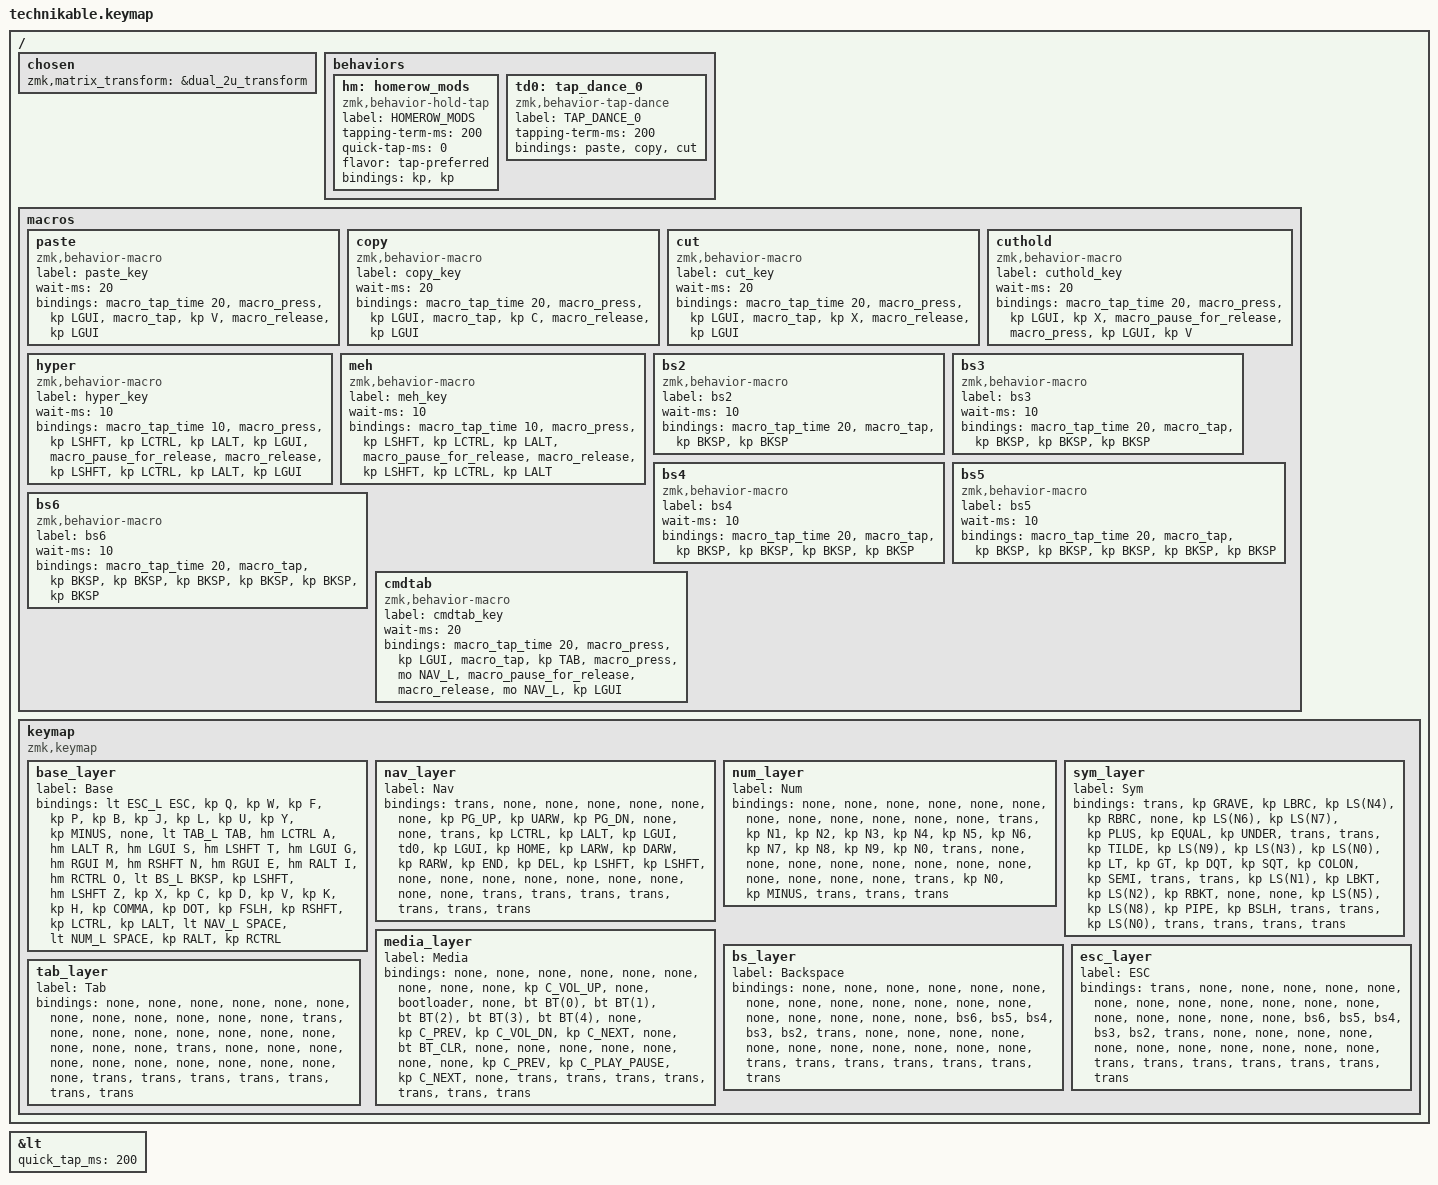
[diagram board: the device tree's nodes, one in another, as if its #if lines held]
/*
 * Copyright (c) 2022 Pete Johanson
 *
 * SPDX-License-Identifier: MIT
 */

#include <behaviors.dtsi>
#include <dt-bindings/zmk/keys.h>
#include <dt-bindings/zmk/bt.h>
#include <dt-bindings/zmk/outputs.h>

#define MOD_TAPS 1

#define TBLE_ORTHO   true
// #define TBLE_MIT     true
// #define TBLE_DUAL_2U true

#define BAS_L 0
#define NAV_L 1
#define NUM_L 2
#define SYM_L 3
#define MEDIA_L 4
#define BS_L 5
#define ESC_L 6
#define TAB_L 7


// Using layer taps on thumbs, having quick tap as well helps w/ repeating space/backspace
&lt { quick_tap_ms = <200>; };

#define BT(n) BT_SEL n

/ {
    chosen {
       zmk,matrix_transform =
#ifdef TBLE_DUAL_2U
                       &dual_2u_transform;
#elif defined(TBLE_MIT)
                       &mit_transform;
#else
                       &ortho_transform;
#endif
    };

    behaviors {
        hm: homerow_mods {
            compatible = "zmk,behavior-hold-tap";
            label = "HOMEROW_MODS";
            #binding-cells = <2>;
            tapping-term-ms = <200>;
            quick-tap-ms = <0>;
            flavor = "tap-preferred";
            bindings = <&kp>, <&kp>;
        };
//        mtmacro: mtmacro {
//            compatible = "zmk,behavior-hold-tap";
//            label = "ModTap_Macros";
//            #binding-cells = <2>;
//            tapping-term-ms = <200>;
//            quick-tap-ms = <0>;
//            flavor = "tap-preferred";
//            bindings = <&>, <&>;
//        };
//        mehd: mehd {
//            compatible = "zmk,behavior-hold-tap";
//            label = "Meh_D";
//            binding-cells = <0>;
//            tapping-term-ms = <200>;
//            quick-tap-ms = <0>;
//            flavor = "tap-preferred";
//            bindings = <&meh>, <&kp D>;
//        };
        td0: tap_dance_0 {
            compatible = "zmk,behavior-tap-dance";
            label = "TAP_DANCE_0";
            #binding-cells = <0>;
            tapping-term-ms = <200>;
            bindings = <&paste>, <&copy>, <&cut>;
        };
    };

    macros {
        paste: paste {
            label = "paste_key";
            compatible = "zmk,behavior-macro";
            #binding-cells = <0>;
            wait-ms = <20>;
            bindings
                = <&macro_tap_time 20>
                , <&macro_press &kp LGUI>
                , <&macro_tap &kp V>
                , <&macro_release &kp LGUI>
                ;
        };
        copy: copy {
            label = "copy_key";
            compatible = "zmk,behavior-macro";
            #binding-cells = <0>;
            wait-ms = <20>;
            bindings
                = <&macro_tap_time 20>
                , <&macro_press &kp LGUI>
                , <&macro_tap &kp C>
                , <&macro_release &kp LGUI>
                ;
        };
        cut: cut {
            label = "cut_key";
            compatible = "zmk,behavior-macro";
            #binding-cells = <0>;
            wait-ms = <20>;
            bindings
                = <&macro_tap_time 20>
                , <&macro_press &kp LGUI>
                , <&macro_tap &kp X>
                , <&macro_release &kp LGUI>
                ;
        };
        cuthold: cuthold {
            label = "cuthold_key";
            compatible = "zmk,behavior-macro";
            #binding-cells = <0>;
            wait-ms = <20>;
            bindings
                = <&macro_tap_time 20>
                , <&macro_press &kp LGUI &kp X>
                , <&macro_pause_for_release>
                , <&macro_press &kp LGUI &kp V>
                ;
        };

        hyper: hyper {
            label = "hyper_key";
            compatible = "zmk,behavior-macro";
            #binding-cells = <0>;
            wait-ms = <10>;
            bindings
                = <&macro_tap_time 10>
                , <&macro_press &kp LSHFT &kp LCTRL &kp LALT &kp LGUI>
                , <&macro_pause_for_release>
                , <&macro_release &kp LSHFT &kp LCTRL &kp LALT &kp LGUI>
                ;
        };
        meh: meh {
            label = "meh_key";
            compatible = "zmk,behavior-macro";
            #binding-cells = <0>;
            wait-ms = <10>;
            bindings
                = <&macro_tap_time 10>
                , <&macro_press &kp LSHFT &kp LCTRL &kp LALT>
                , <&macro_pause_for_release>
                , <&macro_release &kp LSHFT &kp LCTRL &kp LALT>
                ;
        };
        bs2: bs2 {
            label = "bs2";
            compatible = "zmk,behavior-macro";
            #binding-cells = <0>;
            wait-ms = <10>;
            bindings
                = <&macro_tap_time 20>
                , <&macro_tap &kp BKSP &kp BKSP>
                ;
        };
        bs3: bs3 {
            label = "bs3";
            compatible = "zmk,behavior-macro";
            #binding-cells = <0>;
            wait-ms = <10>;
            bindings
                = <&macro_tap_time 20>
                , <&macro_tap &kp BKSP &kp BKSP &kp BKSP>
                ;
        };
        bs4: bs4 {
            label = "bs4";
            compatible = "zmk,behavior-macro";
            #binding-cells = <0>;
            wait-ms = <10>;
            bindings
                = <&macro_tap_time 20>
                , <&macro_tap &kp BKSP &kp BKSP &kp BKSP &kp BKSP>
                ;
        };
        bs5: bs5 {
            label = "bs5";
            compatible = "zmk,behavior-macro";
            #binding-cells = <0>;
            wait-ms = <10>;
            bindings
                = <&macro_tap_time 20>
                , <&macro_tap &kp BKSP &kp BKSP &kp BKSP &kp BKSP &kp BKSP>
                ;
        };
        bs6: bs6 {
            label = "bs6";
            compatible = "zmk,behavior-macro";
            #binding-cells = <0>;
            wait-ms = <10>;
            bindings
                = <&macro_tap_time 20>
                , <&macro_tap &kp BKSP &kp BKSP &kp BKSP &kp BKSP &kp BKSP &kp BKSP>
                ;
        };
        cmdtab: cmdtab {
            label = "cmdtab_key";
            compatible = "zmk,behavior-macro";
            #binding-cells = <0>;
            wait-ms = <20>;
            bindings
                = <&macro_tap_time 20>
                , <&macro_press &kp LGUI>
                , <&macro_tap &kp TAB>
                , <&macro_press &mo NAV_L>
                , <&macro_pause_for_release>
                , <&macro_release &mo NAV_L &kp LGUI>
                ;
        };
    };


//    conditional_layers {
//        compatible = "zmk,conditional-layers";
//	tri_layer {
//	    if-layers = <NAV_L NUM_L>;
//	    then-layer = <SYM_L>;
//	};
//    };

    keymap {
        compatible = "zmk,keymap";

        base_layer {
            label = "Base";
            bindings = <
#ifdef MOD_TAPS
 &lt ESC_L ESC    &kp Q         &kp W      &kp F       &kp P         &kp B          &kp J            &kp L          &kp U       &kp Y       &kp MINUS    &none 
 &lt TAB_L TAB    &hm LCTRL A   &hm LALT R &hm LGUI S  &hm LSHFT T   &hm LGUI G    &hm RGUI M        &hm RSHFT N    &hm RGUI E  &hm RALT I  &hm RCTRL O  &lt BS_L BKSP
 &kp LSHFT  &hm LSHFT Z         &kp X      &kp C       &kp D        &kp V          &kp K            &kp H          &kp COMMA   &kp DOT     &kp FSLH     &kp RSHFT
#else
 &kp ESC    &kp Q      &kp W      &kp F       &kp P          &kp B          &kp J            &kp L          &kp U       &kp Y      &kp MINUS     &none 
 &kp TAB    &kp A      &kp R      &kp S       &kp T          &kp G          &kp M            &kp N          &kp E       &kp I      &kp O        &kp BKSP
 &kp LSHFT  &kp Z      &kp X      &kp C       &kp D          &kp V          &kp K            &kp H          &kp COMMA   &kp DOT    &kp FSLH     &kp RSHFT
#endif
#ifdef TBLE_DUAL_2U
                       &kp LCTRL  &kp LALT      &lt NAV_L SPACE                &lt NUM_L SPACE              &kp RALT    &kp RCTRL
#elif defined(TBLE_MIT)
                       &kp LCTRL  &kp LALT    &mo NAV_L          &kp SPACE                   &mo NUM_L      &kp RALT    &kp RCTRL
#else
                       &meh   &hyper     &mo NAV_L      &kp SPACE      &mo NUM_L         &mo SYM_L      &cmdtab   &none 
#endif
            >;
        };

        nav_layer {
            label = "Nav";
            bindings = <
&trans     &none     &none     &none       &none          &none       &none      &kp PG_UP      &kp UARW       &kp PG_DN    &none      &none 
&trans     &kp LCTRL      &kp LALT      &kp LGUI       &td0        &kp LGUI       &kp HOME      &kp LARW       &kp DARW    &kp RARW   &kp END   &kp DEL
&kp LSHFT     &kp LSHFT      &none      &none       &none       &none        &none       &none        &none    &none    &none    &trans
#ifdef TBLE_DUAL_2U
                      &trans     &trans              &trans                    &trans       &trans         &trans
#elif defined(TBLE_MIT)
                      &trans     &trans      &trans                &trans             &trans      &trans   &trans
#else
                      &trans     &trans      &trans          &trans       &kp RET    &mo MEDIA_L  &trans         &trans
#endif
            >;
        };

        num_layer {
            label = "Num";
            bindings = <
&none    &none   &none     &none      &none   &none    &none    &none         &none       &none       &none     &none
&trans     &kp N1    &kp N2     &kp N3      &kp N4    &kp N5   &kp N6    &kp N7         &kp N8       &kp N9       &kp N0    &trans
&none     &none  &none    &none     &none    &none    &none       &none        &none       &none       &none     &none
#ifdef TBLE_DUAL_2U
                     &trans     &kp N0              &kp MINUS                 &trans            &trans         &trans
#elif defined(TBLE_MIT)
                     &trans     &kp N0      &kp MINUS           &none            &kp ESC        &kp DEL      &trans
#else
                     &trans     &trans     &trans    &trans         &trans     &trans       &trans      &trans
#endif
            >;
        };

        sym_layer {
            label = "Sym";
            bindings = <
&trans     &kp GRAVE   &kp LBRC &kp LS(N4)  &kp RBRC      &none    &kp LS(N6) &kp LS(N7) &kp PLUS       &kp EQUAL   &kp UNDER     &trans
&trans     &kp TILDE  &kp LS(N9) &kp LS(N3)  &kp LS(N0)   &kp LT   &kp GT     &kp DQT      &kp SQT       &kp COLON       &kp SEMI     &trans
&trans     &kp LS(N1)  &kp LBKT &kp LS(N2)  &kp RBKT      &none     &none     &kp LS(N5)      &kp LS(N8)       &kp PIPE       &kp BSLH     &trans
#ifdef TBLE_DUAL_2U
                      &trans     &kp LS(N0)              &trans                    &trans       &trans         &trans
#elif defined(TBLE_MIT)
                      &trans     &kp LS(N0)      &trans                &trans             &trans      &trans   &trans
#else
                      &trans     &kp LS(N0)      &mo MEDIA_L          &kp RET       &trans    &trans  &trans         &trans
#endif
            >;
        };

        media_layer {
            label = "Media";
            bindings = <
&none      &none      &none       &none         &none    &none       &none       &none       &none     &kp C_VOL_UP    &none        &bootloader 
&none        &bt BT(0)  &bt BT(1)  &bt BT(2) &bt BT(3)    &bt BT(4)        &none       &kp C_PREV       &kp C_VOL_DN     &kp C_NEXT    &none           &bt BT_CLR 
&none        &none      &none      &none       &none         &none        &none       &kp C_PREV       &kp C_PLAY_PAUSE     &kp C_NEXT    &none           &trans
#ifdef TBLE_DUAL_2U
                      &trans     &trans              &trans                    &trans       &trans         &trans
#elif defined(TBLE_MIT)
                      &trans     &trans      &trans                &trans             &trans      &trans   &trans
#else
                      &trans     &trans      &trans          &trans       &trans    &trans  &trans         &trans
#endif
            >;
        };
        bs_layer {
            label = "Backspace";
            bindings = <
 &none      &none      &none       &none        &none      &none       &none       &none       &none    &none       &none     &none 
 &none       &none      &none      &none       &none        &none        &bs6        &bs5        &bs4        &bs3    &bs2           &trans
&none        &none      &none      &none       &none         &none        &none        &none        &none        &none   &none           &trans
#ifdef TBLE_DUAL_2U
                      &trans     &trans              &trans                    &trans       &trans         &trans
#elif defined(TBLE_MIT)
                      &trans     &trans      &trans                &trans             &trans      &trans   &trans
#else
                      &trans     &trans      &trans          &trans       &trans    &trans  &trans         &trans
#endif
            >;
        };
        esc_layer {
            label = "ESC";
            bindings = <
 &trans      &none      &none       &none        &none      &none       &none       &none       &none    &none       &none     &none 
 &none       &none      &none      &none       &none        &none        &bs6        &bs5        &bs4        &bs3    &bs2           &trans
&none        &none      &none      &none       &none         &none        &none        &none        &none        &none   &none           &trans
#ifdef TBLE_DUAL_2U
                      &trans     &trans              &trans                    &trans       &trans         &trans
#elif defined(TBLE_MIT)
                      &trans     &trans      &trans                &trans             &trans      &trans   &trans
#else
                      &trans     &trans      &trans          &trans       &trans    &trans  &trans         &trans
#endif
            >;
        };
        tab_layer {
            label = "Tab";
            bindings = <
 &none      &none      &none       &none        &none      &none       &none       &none       &none    &none       &none     &none 
 &trans       &none      &none      &none       &none        &none         &none      &none      &none       &none        &none         &trans
&none        &none      &none      &none       &none         &none        &none        &none        &none        &none   &none           &trans
#ifdef TBLE_DUAL_2U
                      &trans     &trans              &trans                    &trans       &trans         &trans
#elif defined(TBLE_MIT)
                      &trans     &trans      &trans                &trans             &trans      &trans   &trans
#else
                      &trans     &trans      &trans          &trans       &trans    &trans  &trans         &trans
#endif
            >;
        };
    };
};

